# MIMXRT1052 register map
Vendor: nxp.com; File version: 1.0
CPU: CM7 r0p1, little endian, MPU, FPU, VTOR, 4 interrupt priority bits
Registers are 32-bit, read-write, reset 0x0 unless marked. A register's access mark holds for its fields unless they carry their own. Offsets are from the block's base; [hi:lo] are bit positions; {n}, {i} and the like mark numbered series.

## IOMUXC_SNVS_GPR — IOMUXC
Base 0x400A4000; register names take the prefix IOMUXC_SNVS_GPR_
{0x0+4i} GPR{i} ro (i=0..2) — GPR{i} General Purpose Register
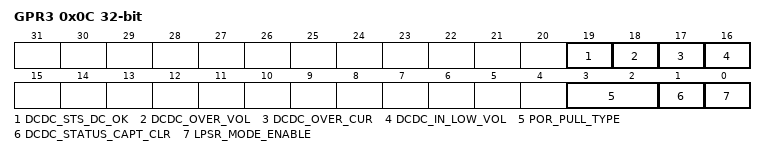
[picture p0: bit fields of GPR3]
0x0C GPR3 — GPR3 General Purpose Register
  [19] DCDC_STS_DC_OK ro — DCDC status OK
    0=DCDC is ramping up and not ready; 1=DCDC is ready
  [18] DCDC_OVER_VOL ro — DCDC output over voltage alert
    0=No over voltage detected; 1=Over voltage detected
  [17] DCDC_OVER_CUR ro — DCDC output over current alert
    0=No over current detected; 1=Over current detected
  [16] DCDC_IN_LOW_VOL ro — DCDC_IN low voltage detect.
    0=DCDC_IN is ok; 1=DCDC_IN is too low
  [3:2] POR_PULL_TYPE — POR_B pad control
    0=100 Ohm pull up enabled for POR_B always; 1=Disable pull in SNVS mode, 100 Ohm pull up enabled otherwise; 2=Disable pull of POR_B always; 3=100 Ohm pull down enabled in SNVS mode, 100 Ohm pull up enabled otherwise
  [1] DCDC_STATUS_CAPT_CLR — DCDC captured status clear
  [0] LPSR_MODE_ENABLE — Set to enable LPSR mode.
    0=SNVS domain will reset when system reset happens; 1=SNVS domain will only reset with SNVS POR

## FLEXRAM
Base 0x400B0000
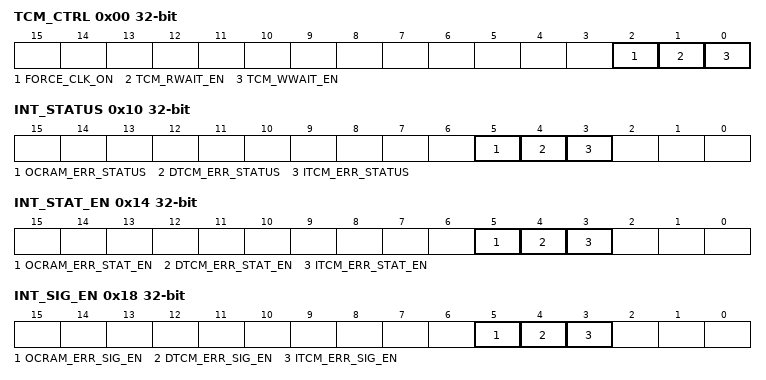
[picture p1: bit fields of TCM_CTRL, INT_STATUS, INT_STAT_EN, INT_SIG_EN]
0x00 TCM_CTRL — TCM CRTL Register
  [2] FORCE_CLK_ON — Force RAM Clock Always On
  [1] TCM_RWAIT_EN — TCM Read Wait Mode Enable
    0=TCM read fast mode: Read RAM accesses are expected to be finished in 1-cycle; 1=TCM read wait mode: Read RAM accesses are expected to be finished in 2-cycles
  [0] TCM_WWAIT_EN — TCM Write Wait Mode Enable
    0=TCM write fast mode: Write RAM accesses are expected to be finished in 1-cycle; 1=TCM write wait mode: Write RAM accesses are expected to be finished in 2-cycles
0x10 INT_STATUS — Interrupt Status Register
  [5] OCRAM_ERR_STATUS write-1-clears — OCRAM Access Error Status
    0=OCRAM access error does not happen; 1=OCRAM access error happens
  [4] DTCM_ERR_STATUS write-1-clears — DTCM Access Error Status
    0=DTCM access error does not happen; 1=DTCM access error happens
  [3] ITCM_ERR_STATUS write-1-clears — ITCM Access Error Status
    0=ITCM access error does not happen; 1=ITCM access error happens
0x14 INT_STAT_EN — Interrupt Status Enable Register
  [all] fields
    0=Masked; 1=Enabled
  [5] OCRAM_ERR_STAT_EN — OCRAM Access Error Status Enable
  [4] DTCM_ERR_STAT_EN — DTCM Access Error Status Enable
  [3] ITCM_ERR_STAT_EN — ITCM Access Error Status Enable
0x18 INT_SIG_EN — Interrupt Enable Register
  [all] fields
    0=Masked; 1=Enabled
  [5] OCRAM_ERR_SIG_EN — OCRAM Access Error Interrupt Enable
  [4] DTCM_ERR_SIG_EN — DTCM Access Error Interrupt Enable
  [3] ITCM_ERR_SIG_EN — ITCM Access Error Interrupt Enable

## EWM
Base 0x400B4000
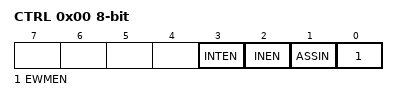
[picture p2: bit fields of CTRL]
0x00 CTRL 8-bit — Control Register
  [3] INTEN — Interrupt Enable.
  [2] INEN rw-once — Input Enable.
  [1] ASSIN rw-once — EWM_in's Assertion State Select.
  [0] EWMEN rw-once — EWM enable.
0x01 SERV 8-bit — Service Register
  [7:0] SERVICE
0x02 CMPL 8-bit rw-once — Compare Low Register
  [7:0] COMPAREL
0x03 CMPH 8-bit rw-once reset 0xFF — Compare High Register
  [7:0] COMPAREH
0x04 CLKCTRL 8-bit rw-once — Clock Control Register
  [1:0] CLKSEL
0x05 CLKPRESCALER 8-bit rw-once — Clock Prescaler Register
  [7:0] CLK_DIV

## WDOG1 — WDOG
Base 0x400B8000
Same registers: WDOG2 0x400D0000
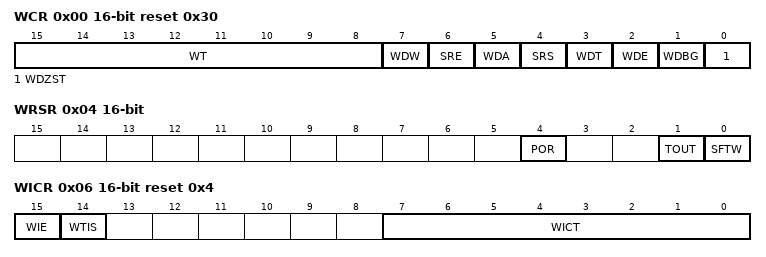
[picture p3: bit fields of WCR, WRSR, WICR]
0x00 WCR 16-bit reset 0x30 — Watchdog Control Register
  [15:8] WT
    0=- 0.5 Seconds (Default); 1=- 1.0 Seconds; 2=- 1.5 Seconds; 3=- 2.0 Seconds; 255=- 128 Seconds
  [7] WDW
    0=Continue WDOG timer operation (Default); 1=Suspend WDOG timer operation
  [6] SRE — software reset extension, an option way to generate software reset
    0=using original way to generate software reset (default); 1=using new way to generate software reset
  [5] WDA
    0=Assert WDOG_B output; 1=No effect on system (Default)
  [4] SRS
    0=Assert system reset signal; 1=No effect on the system (Default)
  [3] WDT
    0=No effect on WDOG_B (Default); 1=Assert WDOG_B upon a Watchdog Time-out event
  [2] WDE
    0=Disable the Watchdog (Default); 1=Enable the Watchdog
  [1] WDBG
    0=Continue WDOG timer operation (Default); 1=Suspend the watchdog timer
  [0] WDZST
    0=Continue timer operation (Default); 1=Suspend the watchdog timer
0x02 WSR 16-bit — Watchdog Service Register
  [15:0] WSR
    0x5555=Write to the Watchdog Service Register (WDOG_WSR); 0xAAAA=Write to the Watchdog Service Register (WDOG_WSR)
0x04 WRSR 16-bit ro — Watchdog Reset Status Register
  [4] POR
    0=Reset is not the result of a power on reset; 1=Reset is the result of a power on reset
  [1] TOUT
    0=Reset is not the result of a WDOG timeout; 1=Reset is the result of a WDOG timeout
  [0] SFTW
    0=Reset is not the result of a software reset; 1=Reset is the result of a software reset
0x06 WICR 16-bit reset 0x4 — Watchdog Interrupt Control Register
  [15] WIE
    0=Disable Interrupt (Default); 1=Enable Interrupt
  [14] WTIS write-1-clears
    0=No interrupt has occurred (Default); 1=Interrupt has occurred
  [7:0] WICT
    0=WICT[7:0] = Time duration between interrupt and time-out is 0 seconds; 1=WICT[7:0] = Time duration between interrupt and time-out is 0.5 seconds; 4=WICT[7:0] = Time duration between interrupt and time-out is 2 seconds (Default); 255=WICT[7:0] = Time duration between interrupt and time-out is 127.5 seconds
0x08 WMCR 16-bit reset 0x1 — Watchdog Miscellaneous Control Register
  [0] PDE
    0=Power Down Counter of WDOG is disabled; 1=Power Down Counter of WDOG is enabled (Default)
